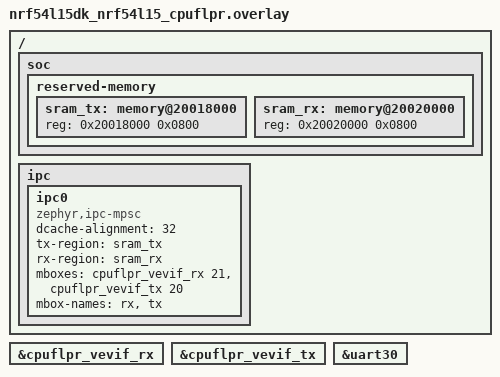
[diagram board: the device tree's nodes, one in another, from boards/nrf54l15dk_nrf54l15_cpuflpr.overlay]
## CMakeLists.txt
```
#
# Copyright (c) 2026 Nordic Semiconductor ASA
#
# SPDX-License-Identifier: Apache-2.0
#

cmake_minimum_required(VERSION 3.20.0)

find_package(Zephyr REQUIRED HINTS $ENV{ZEPHYR_BASE})
project(ipc_service_remote)

target_include_directories(app PRIVATE ${CMAKE_CURRENT_SOURCE_DIR}/../common)

target_sources(app PRIVATE src/main.c)

if(CONFIG_STATS)
  target_sources(app PRIVATE ../common/stats_print.c)
endif()
```

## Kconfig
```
source "Kconfig.zephyr"

config TEST_MULTI_ENDPOINT
	bool
	default y if $(dt_nodelabel_has_compat,ipc0,$(DT_COMPAT_ZEPHYR_IPC_ICBMSG))
	default y if $(dt_nodelabel_has_compat,ipc0,$(DT_COMPAT_ZEPHYR_IPC_MPSC))
	default n
```

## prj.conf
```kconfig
CONFIG_IPC_SERVICE=y
CONFIG_MBOX=y
CONFIG_LOG=y
CONFIG_GPIO=n
CONFIG_CPU_LOAD=y
```

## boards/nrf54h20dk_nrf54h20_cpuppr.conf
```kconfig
CONFIG_MBOX=y
CONFIG_WATCHDOG=y
```

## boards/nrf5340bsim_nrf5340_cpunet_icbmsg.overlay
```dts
/*
 * SPDX-License-Identifier: Apache-2.0
 */

#include "nrf5340dk_nrf5340_cpunet_icbmsg.overlay"
```

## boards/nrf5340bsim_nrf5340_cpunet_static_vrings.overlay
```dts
/*
 * SPDX-License-Identifier: Apache-2.0
 */

#include "nrf5340dk_nrf5340_cpunet_static_vrings.overlay"
```

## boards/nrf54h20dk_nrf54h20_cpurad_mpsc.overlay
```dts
&ipc0 {
	compatible = "zephyr,ipc-mpsc";
	/delete-property/tx-blocks;
	/delete-property/rx-blocks;
};
```

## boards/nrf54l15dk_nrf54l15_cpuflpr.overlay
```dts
/*
 * Copyright (c) 2024 Nordic Semiconductor ASA
 *
 * SPDX-License-Identifier: Apache-2.0
 */

/ {
	soc {
		reserved-memory {
			#address-cells = <1>;
			#size-cells = <1>;

			sram_tx: memory@20018000 {
				reg = <0x20018000 0x0800>;
			};

			sram_rx: memory@20020000 {
				reg = <0x20020000 0x0800>;
			};
		};
	};

	ipc {
		ipc0: ipc0 {
			compatible = "zephyr,ipc-mpsc", "zephyr,ipc-icmsg";
			dcache-alignment = <32>;
			tx-region = <&sram_tx>;
			rx-region = <&sram_rx>;
			mboxes = <&cpuflpr_vevif_rx 21>, <&cpuflpr_vevif_tx 20>;
			mbox-names = "rx", "tx";
			status = "okay";
		};
	};
};

&cpuflpr_vevif_rx {
	status = "okay";
};

&cpuflpr_vevif_tx {
	status = "okay";
};

&uart30 {
	/delete-property/ hw-flow-control;
};
```

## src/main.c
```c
/*
 * Copyright (c) 2026 Nordic Semiconductor ASA
 *
 * SPDX-License-Identifier: Apache-2.0
 */

#include <zephyr/kernel.h>
#include <zephyr/device.h>
#include <zephyr/debug/cpu_load.h>
#include <zephyr/ipc/ipc_service.h>
#include <zephyr/logging/log.h>
#include "common.h"

LOG_MODULE_REGISTER(remote, LOG_LEVEL_DBG);

struct test_data {
#if defined(CONFIG_MULTITHREADING)
	struct k_sem sem;
#else
	atomic_t bound_flag;
#endif
	struct ipc_ept ep;
	struct ipc_ept_cfg cfg;
};

struct test_data tdata[1];
static char test_name[128];
static uint32_t test_start_stamp;

static void ep_bound(void *priv)
{
	struct test_data *tdata = priv;
#if defined(CONFIG_MULTITHREADING)
	k_sem_give(&tdata->sem);
#else
	tdata->bound_flag = 1;
#endif
	LOG_INF("Ep:%s bounded", tdata->cfg.name);
}

void test_start(struct test_data *tdata, const uint8_t *data, size_t len)
{
	memcpy(test_name, data, len);
	if (IS_ENABLED(CONFIG_CPU_LOAD)) {
		(void)cpu_load_get(true);
	}
	test_start_stamp = k_cycle_get_32();
}

void test_end(struct test_data *tdata, const uint8_t *data, size_t len)
{
	uint32_t t = k_cycle_get_32() - test_start_stamp;

	t = k_cyc_to_us_floor32(t);

	printk("Test %s took %d us ", test_name, t);
	if (IS_ENABLED(CONFIG_CPU_LOAD)) {
		uint32_t load = cpu_load_get(true);

		printk("CPU load: %d.%d", load / 10, load % 10);
	}
	printk("\n");

}

static void ep_recv(const void *data, size_t len, void *priv)
{
	struct test_data *tdata = priv;
	const struct data_packet *pkt = data;

	switch (pkt->type) {
	case TYPE_RSP:
	{
		static bool once;
		int ret;

		ret = ipc_service_send(&tdata->ep, data, len);
		if ((ret < 0) && !once) {
			once = true;
			LOG_ERR("failed to send len:%d", len);
		}
		break;
	}
	case TYPE_TEST_START:
		test_start(tdata, pkt->data, len - sizeof(pkt->type));
		break;
	case TYPE_TEST_END:
		test_end(tdata, pkt->data, len - sizeof(pkt->type));
		break;
	default:
		break;
	}
}

int main(void)
{
	const struct device *ipc0 = DEVICE_DT_GET(DT_NODELABEL(ipc0));
	int ret;


	LOG_INF("IPC-service REMOTE demo started");

	ret = ipc_service_open_instance(ipc0);
	if ((ret < 0) && (ret != -EALREADY)) {
		LOG_ERR("ipc_service_open_instance() failure");
		return ret;
	}

	tdata[0].cfg.name = "ep0";
	tdata[0].cfg.cb.bound = ep_bound;
	tdata[0].cfg.cb.received = ep_recv;
	tdata[0].cfg.priv = &tdata[0];
#if defined(CONFIG_MULTITHREADING)
	k_sem_init(&tdata[0].sem, 0, 1);
#else
	tdata[0].bound_flag = 0;
#endif

	ret = ipc_service_register_endpoint(ipc0, &tdata[0].ep, &tdata[0].cfg);
	if (ret < 0) {
		LOG_ERR("ipc_service_register_endpoint() failure");
		return ret;
	}

#if defined(CONFIG_MULTITHREADING)
	k_sem_take(&tdata[0].sem, K_FOREVER);
#else
	while (tdata[0].bound_flag != 0) {
	};
#endif

	k_sleep(K_FOREVER);
	return 0;
}
```
